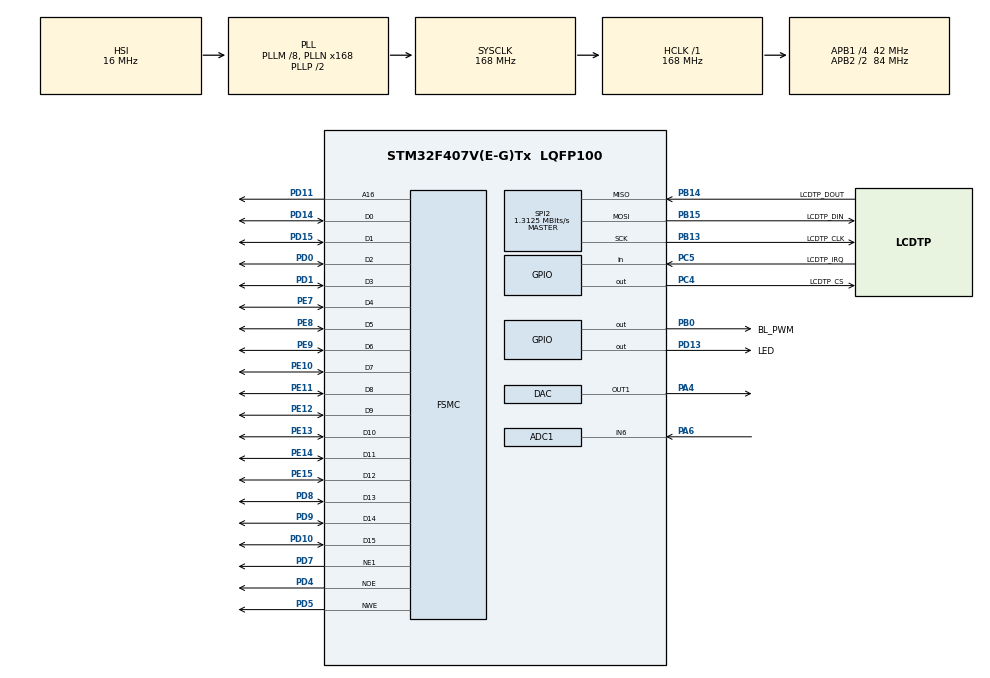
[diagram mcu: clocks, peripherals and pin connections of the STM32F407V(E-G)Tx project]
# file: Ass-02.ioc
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ADC1.Channel-0\#ChannelRegularConversion=ADC_CHANNEL_6
ADC1.NbrOfConversionFlag=1
ADC1.Rank-0\#ChannelRegularConversion=1
ADC1.SamplingTime-0\#ChannelRegularConversion=ADC_SAMPLETIME_3CYCLES
ADC1.master=1
DAC.DAC_Trigger=DAC_TRIGGER_T2_TRGO
Dma.DAC1.0.Direction=DMA_MEMORY_TO_PERIPH
Dma.DAC1.0.FIFOMode=DMA_FIFOMODE_DISABLE
Dma.DAC1.0.Instance=DMA1_Stream5
Dma.DAC1.0.MemDataAlignment=DMA_MDATAALIGN_WORD
Dma.DAC1.0.MemInc=DMA_MINC_ENABLE
Dma.DAC1.0.Mode=DMA_CIRCULAR
Dma.DAC1.0.PeriphDataAlignment=DMA_PDATAALIGN_WORD
Dma.DAC1.0.PeriphInc=DMA_PINC_DISABLE
Dma.DAC1.0.Priority=DMA_PRIORITY_LOW
Dma.Request0=DAC1
FREERTOS.Queues01=CtrlQueue,16,uint32_t,0,Dynamic,NULL,NULL
FREERTOS.Tasks01=InitTask,2,128,StartInitTask,As weak,NULL,Dynamic,NULL,NULL;ControlTask,-3,128,StartControlTask,As weak,NULL,Dynamic,NULL,NULL;TouchPanelTask,-3,128,StartTouchPanelTask,As weak,NULL,Dynamic,NULL,NULL;ADCTask,-3,128,StartADCTask,As weak,NULL,Dynamic,NULL,NULL;GrinderTimTask,-3,128,StartGrinderTimerTask,As weak,NULL,Dynamic,NULL,NULL;LCDTask,-3,128,StartLCDTask,As weak,NULL,Dynamic,NULL,NULL
FREERTOS.Timers01=PauseTimer,PauseCallback,osTimerOnce,As weak,NULL,Dynamic,NULL
FREERTOS.configUSE_NEWLIB_REENTRANT=1
FREERTOS.configUSE_TIMERS=1
FSMC.AddressSetupTime1=4
FSMC.BusTurnAroundDuration1=0
FSMC.DataSetupTime1=40
Mcu.Family=STM32F4
Mcu.Name=STM32F407V(E-G)Tx
Mcu.Package=LQFP100
NVIC.DMA1_Stream5_IRQn=true\:5\:0\:false\:false\:true\:true\:false\:true\:true
NVIC.PriorityGroup=NVIC_PRIORITYGROUP_4
NVIC.SPI2_IRQn=true\:5\:0\:false\:false\:true\:true\:true\:true\:true
NVIC.TIM6_DAC_IRQn=true\:5\:0\:false\:false\:true\:false\:false\:true\:true
NVIC.TimeBase=TIM6_DAC_IRQn
NVIC.TimeBaseIP=TIM6
PA4.Signal=COMP_DAC1_group
PA6.Signal=ADCx_IN6
PB0.GPIO_Label=BL_PWM
PB0.PinState=GPIO_PIN_SET
PB0.Signal=GPIO_Output
PB13.GPIO_Label=LCDTP_CLK
PB13.Mode=Full_Duplex_Master
PB13.Signal=SPI2_SCK
PB14.GPIO_Label=LCDTP_DOUT
PB14.Mode=Full_Duplex_Master
PB14.Signal=SPI2_MISO
PB15.GPIO_Label=LCDTP_DIN
PB15.Mode=Full_Duplex_Master
PB15.Signal=SPI2_MOSI
PC4.GPIO_Label=LCDTP_CS
PC4.GPIO_PuPd=GPIO_PULLDOWN
PC4.Signal=GPIO_Output
PC5.GPIO_Label=LCDTP_IRQ
PC5.GPIO_PuPd=GPIO_NOPULL
PC5.Signal=GPIO_Input
PD0.Mode=16b-d1
PD0.Signal=FSMC_D2
PD1.Mode=16b-d1
PD1.Signal=FSMC_D3
PD10.Mode=16b-d1
PD10.Signal=FSMC_D15
PD11.Mode=A16_1
PD11.Signal=FSMC_A16
PD13.GPIO_Label=LED
PD13.GPIO_Speed=GPIO_SPEED_FREQ_LOW
PD13.Signal=GPIO_Output
PD14.Mode=16b-d1
PD14.Signal=FSMC_D0
PD15.Mode=16b-d1
PD15.Signal=FSMC_D1
PD4.Mode=Lcd1
PD4.Signal=FSMC_NOE
PD5.Mode=Lcd1
PD5.Signal=FSMC_NWE
PD7.Mode=NorPsramChipSelect1_1
PD7.Signal=FSMC_NE1
PD8.Mode=16b-d1
PD8.Signal=FSMC_D13
PD9.Mode=16b-d1
PD9.Signal=FSMC_D14
PE10.Mode=16b-d1
PE10.Signal=FSMC_D7
PE11.Mode=16b-d1
PE11.Signal=FSMC_D8
PE12.Mode=16b-d1
PE12.Signal=FSMC_D9
PE13.Mode=16b-d1
PE13.Signal=FSMC_D10
PE14.Mode=16b-d1
PE14.Signal=FSMC_D11
PE15.Mode=16b-d1
PE15.Signal=FSMC_D12
PE7.Mode=16b-d1
PE7.Signal=FSMC_D4
PE8.Mode=16b-d1
PE8.Signal=FSMC_D5
PE9.Mode=16b-d1
PE9.Signal=FSMC_D6
ProjectManager.HeapSize=0x200
ProjectManager.StackSize=0x400
ProjectManager.TargetToolchain=STM32CubeIDE
RCC.48MHZClocksFreq_Value=84000000
RCC.AHBFreq_Value=168000000
RCC.APB1CLKDivider=RCC_HCLK_DIV4
RCC.APB1Freq_Value=42000000
RCC.APB1TimFreq_Value=84000000
RCC.APB2CLKDivider=RCC_HCLK_DIV2
RCC.APB2Freq_Value=84000000
RCC.APB2TimFreq_Value=168000000
RCC.CortexFreq_Value=168000000
RCC.HCLKFreq_Value=168000000
RCC.HSE_VALUE=8000000
RCC.HSI_VALUE=16000000
RCC.LSE_VALUE=32768
RCC.PLLM=8
RCC.PLLN=168
RCC.SYSCLKFreq_VALUE=168000000
RCC.SYSCLKSource=RCC_SYSCLKSOURCE_PLLCLK
RCC.VCOOutputFreq_Value=336000000
SH.ADCx_IN6.0=ADC1_IN6,IN6
SH.COMP_DAC1_group.0=DAC_OUT1,DAC_OUT1
SPI2.BaudRatePrescaler=SPI_BAUDRATEPRESCALER_32
SPI2.CalculateBaudRate=1.3125 MBits/s
SPI2.Direction=SPI_DIRECTION_2LINES
SPI2.Mode=SPI_MODE_MASTER
SPI2.VirtualType=VM_MASTER
TIM2.Period=20999
TIM2.TIM_MasterOutputTrigger=TIM_TRGO_UPDATE
VP_FREERTOS_VS_CMSIS_V1.Mode=CMSIS_V1
VP_SYS_VS_tim6.Mode=TIM6
VP_TIM2_VS_ClockSourceINT.Mode=Internal
board=LCD

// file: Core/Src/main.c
/* USER CODE BEGIN Header */
/**
  ******************************************************************************
  * @file           : main.c
  * @brief          : Main program body
  ******************************************************************************
  * @attention
  *
  * Copyright (c) 2022 STMicroelectronics.
  * All rights reserved.
  *
  * This software is licensed under terms that can be found in the LICENSE file
  * in the root directory of this software component.
  * If no LICENSE file comes with this software, it is provided AS-IS.
  *
  ******************************************************************************
  */
/* USER CODE END Header */
#include "main.h"
#include "cmsis_os.h"
#include "adc.h"
#include "dac.h"
#include "dma.h"
#include "spi.h"
#include "tim.h"
#include "gpio.h"
#include "fsmc.h"

/* USER CODE BEGIN Includes */
#include "openx07v_c_lcd.h"
#include "touch_panel.h"
#include <stdio.h>
/* USER CODE END Includes */

/* USER CODE BEGIN PV */
/* Private variables ---------------------------------------------------------*/

/* USER CODE END PV */

void SystemClock_Config(void);
void MX_FREERTOS_Init(void);
/* USER CODE BEGIN PFP */
/* Private function prototypes -----------------------------------------------*/
extern void initialise_monitor_handles(void);
/* USER CODE END PFP */

int main(void)
{
  /* USER CODE BEGIN 1 */
  initialise_monitor_handles();
  /* USER CODE END 1 */

  /* MCU Configuration--------------------------------------------------------*/

  /* Reset of all peripherals, Initializes the Flash interface and the Systick. */
  HAL_Init();

  /* Configure the system clock */
  SystemClock_Config();

  /* Initialize all configured peripherals */
  MX_GPIO_Init();
  MX_FSMC_Init();
  MX_DMA_Init();
  MX_SPI2_Init();
  MX_DAC_Init();
  MX_TIM2_Init();
  MX_ADC1_Init();

  /* Call init function for freertos objects (in freertos.c) */
  MX_FREERTOS_Init();

  /* Start scheduler */
  osKernelStart();

  /* We should never get here as control is now taken by the scheduler */
  /* Infinite loop */
  while (1)
  {

    /* USER CODE BEGIN 3 */
	printf("osKernel Exit Error\n");
  }
  /* USER CODE END 3 */
}

void SystemClock_Config(void)
{
  RCC_OscInitTypeDef RCC_OscInitStruct = {0};
  RCC_ClkInitTypeDef RCC_ClkInitStruct = {0};

  /** Configure the main internal regulator output voltage
  */
  __HAL_RCC_PWR_CLK_ENABLE();
  __HAL_PWR_VOLTAGESCALING_CONFIG(PWR_REGULATOR_VOLTAGE_SCALE1);

  /** Initializes the RCC Oscillators according to the specified parameters
  * in the RCC_OscInitTypeDef structure.
  */
  RCC_OscInitStruct.OscillatorType = RCC_OSCILLATORTYPE_HSI;
  RCC_OscInitStruct.HSIState = RCC_HSI_ON;
  RCC_OscInitStruct.HSICalibrationValue = RCC_HSICALIBRATION_DEFAULT;
  RCC_OscInitStruct.PLL.PLLState = RCC_PLL_ON;
  RCC_OscInitStruct.PLL.PLLSource = RCC_PLLSOURCE_HSI;
  RCC_OscInitStruct.PLL.PLLM = 8;
  RCC_OscInitStruct.PLL.PLLN = 168;
  RCC_OscInitStruct.PLL.PLLP = RCC_PLLP_DIV2;
  RCC_OscInitStruct.PLL.PLLQ = 4;
  if (HAL_RCC_OscConfig(&RCC_OscInitStruct) != HAL_OK)
  {
    Error_Handler();
  }

  /** Initializes the CPU, AHB and APB buses clocks
  */
  RCC_ClkInitStruct.ClockType = RCC_CLOCKTYPE_HCLK|RCC_CLOCKTYPE_SYSCLK
                              |RCC_CLOCKTYPE_PCLK1|RCC_CLOCKTYPE_PCLK2;
  RCC_ClkInitStruct.SYSCLKSource = RCC_SYSCLKSOURCE_PLLCLK;
  RCC_ClkInitStruct.AHBCLKDivider = RCC_SYSCLK_DIV1;
  RCC_ClkInitStruct.APB1CLKDivider = RCC_HCLK_DIV4;
  RCC_ClkInitStruct.APB2CLKDivider = RCC_HCLK_DIV2;

  if (HAL_RCC_ClockConfig(&RCC_ClkInitStruct, FLASH_LATENCY_5) != HAL_OK)
  {
    Error_Handler();
  }
}

void HAL_TIM_PeriodElapsedCallback(TIM_HandleTypeDef *htim)
{
  if (htim->Instance == TIM6) {
    HAL_IncTick();
  }
}

void Error_Handler(void)
{
  __disable_irq();
  while (1)
  {
  }
}

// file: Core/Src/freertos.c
/* USER CODE BEGIN Header */
/**
  ******************************************************************************
  * File Name          : freertos.c
  * Description        : Code for freertos applications
  ******************************************************************************
  * @attention
  *
  * Copyright (c) 2022 STMicroelectronics.
  * All rights reserved.
  *
  * This software is licensed under terms that can be found in the LICENSE file
  * in the root directory of this software component.
  * If no LICENSE file comes with this software, it is provided AS-IS.
  *
  ******************************************************************************
  */
/* USER CODE END Header */

#include "FreeRTOS.h"
#include "task.h"
#include "main.h"
#include "cmsis_os.h"

/* USER CODE BEGIN Includes */
#include "Ass-02.h"
/* USER CODE END Includes */

osThreadId InitTaskHandle;
osThreadId ControlTaskHandle;
osThreadId TouchPanelTaskHandle;
osThreadId ADCTaskHandle;
osThreadId GrinderTimTaskHandle;
osThreadId LCDTaskHandle;
osMessageQId CtrlQueueHandle;
osTimerId PauseTimerHandle;

void StartInitTask(void const * argument);
void StartControlTask(void const * argument);
void StartTouchPanelTask(void const * argument);
void StartADCTask(void const * argument);
void StartGrinderTimerTask(void const * argument);
void StartLCDTask(void const * argument);
void PauseCallback(void const * argument);

void MX_FREERTOS_Init(void); /* (MISRA C 2004 rule 8.1) */

/* GetIdleTaskMemory prototype (linked to static allocation support) */
void vApplicationGetIdleTaskMemory( StaticTask_t **ppxIdleTaskTCBBuffer, StackType_t **ppxIdleTaskStackBuffer, uint32_t *pulIdleTaskStackSize );

/* GetTimerTaskMemory prototype (linked to static allocation support) */
void vApplicationGetTimerTaskMemory( StaticTask_t **ppxTimerTaskTCBBuffer, StackType_t **ppxTimerTaskStackBuffer, uint32_t *pulTimerTaskStackSize );

/* USER CODE BEGIN GET_IDLE_TASK_MEMORY */
static StaticTask_t xIdleTaskTCBBuffer;
static StackType_t xIdleStack[configMINIMAL_STACK_SIZE];

void vApplicationGetIdleTaskMemory( StaticTask_t **ppxIdleTaskTCBBuffer, StackType_t **ppxIdleTaskStackBuffer, uint32_t *pulIdleTaskStackSize )
{
  *ppxIdleTaskTCBBuffer = &xIdleTaskTCBBuffer;
  *ppxIdleTaskStackBuffer = &xIdleStack[0];
  *pulIdleTaskStackSize = configMINIMAL_STACK_SIZE;
  /* place for user code */
}
/* USER CODE END GET_IDLE_TASK_MEMORY */

/* USER CODE BEGIN GET_TIMER_TASK_MEMORY */
static StaticTask_t xTimerTaskTCBBuffer;
static StackType_t xTimerStack[configTIMER_TASK_STACK_DEPTH];

void vApplicationGetTimerTaskMemory( StaticTask_t **ppxTimerTaskTCBBuffer, StackType_t **ppxTimerTaskStackBuffer, uint32_t *pulTimerTaskStackSize )
{
  *ppxTimerTaskTCBBuffer = &xTimerTaskTCBBuffer;
  *ppxTimerTaskStackBuffer = &xTimerStack[0];
  *pulTimerTaskStackSize = configTIMER_TASK_STACK_DEPTH;
  /* place for user code */
}
/* USER CODE END GET_TIMER_TASK_MEMORY */

void MX_FREERTOS_Init(void) {

  /* Create the timer(s) */
  /* definition and creation of PauseTimer */
  osTimerDef(PauseTimer, PauseCallback);
  PauseTimerHandle = osTimerCreate(osTimer(PauseTimer), osTimerOnce, NULL);

  /* Create the queue(s) */
  /* definition and creation of CtrlQueue */
  osMessageQDef(CtrlQueue, 16, uint32_t);
  CtrlQueueHandle = osMessageCreate(osMessageQ(CtrlQueue), NULL);

  /* Create the thread(s) */
  /* definition and creation of InitTask */
  osThreadDef(InitTask, StartInitTask, osPriorityHigh, 0, 128);
  InitTaskHandle = osThreadCreate(osThread(InitTask), NULL);

  /* definition and creation of ControlTask */
  osThreadDef(ControlTask, StartControlTask, osPriorityIdle, 0, 128);
  ControlTaskHandle = osThreadCreate(osThread(ControlTask), NULL);

  /* definition and creation of TouchPanelTask */
  osThreadDef(TouchPanelTask, StartTouchPanelTask, osPriorityIdle, 0, 128);
  TouchPanelTaskHandle = osThreadCreate(osThread(TouchPanelTask), NULL);

  /* definition and creation of ADCTask */
  osThreadDef(ADCTask, StartADCTask, osPriorityIdle, 0, 128);
  ADCTaskHandle = osThreadCreate(osThread(ADCTask), NULL);

  /* definition and creation of GrinderTimTask */
  osThreadDef(GrinderTimTask, StartGrinderTimerTask, osPriorityIdle, 0, 128);
  GrinderTimTaskHandle = osThreadCreate(osThread(GrinderTimTask), NULL);

  /* definition and creation of LCDTask */
  osThreadDef(LCDTask, StartLCDTask, osPriorityIdle, 0, 128);
  LCDTaskHandle = osThreadCreate(osThread(LCDTask), NULL);

}

__weak void StartInitTask(void const * argument)
{
  for(;;)
  {
    osDelay(1);
  }
}

__weak void StartControlTask(void const * argument)
{
  for(;;)
  {
    osDelay(1);
  }
}

__weak void StartTouchPanelTask(void const * argument)
{
  for(;;)
  {
    osDelay(1);
  }
}

__weak void StartADCTask(void const * argument)
{
  for(;;)
  {
    osDelay(1);
  }
}

__weak void StartGrinderTimerTask(void const * argument)
{
  for(;;)
  {
    osDelay(1);
  }
}

__weak void StartLCDTask(void const * argument)
{
  for(;;)
  {
    osDelay(1);
  }
}

/* PauseCallback function */
__weak void PauseCallback(void const * argument)
{
}
